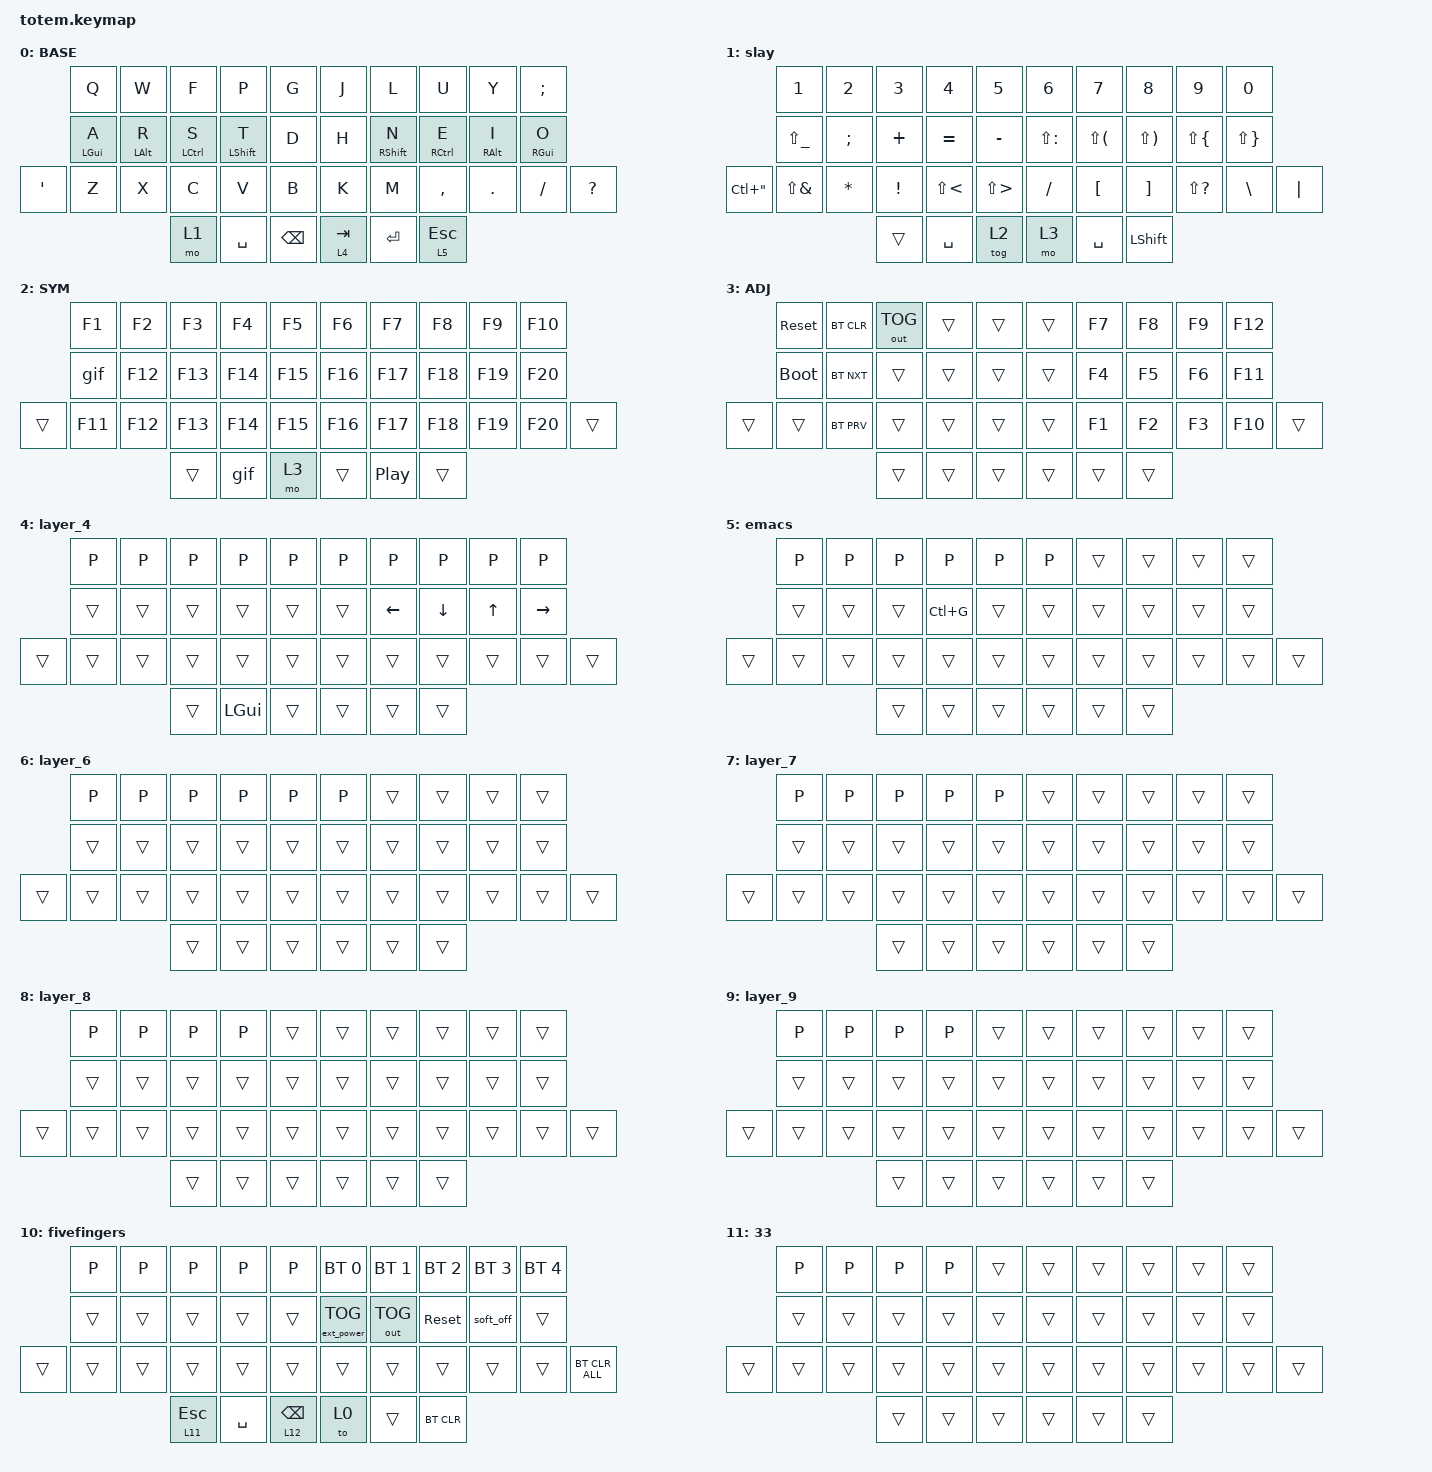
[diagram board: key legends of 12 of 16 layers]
//
//                                                        ▀▀▀▀▀     ▀▀▀▀▀          ▀▀█▀▀
//                                                        ▄▀▀▀▄  ▄  ▄▀▀▀▄  ▄  ▄▀▀▀▄  █  ▄▀▀▀▄
//                                                        █   █  █  █   █  █  █   █  █  █   █
//                                                         ▀▀▀   █   ▀▀▀   █   ▀▀▀   ▀   ▀▀▀
//                                                               █      ▄▄▄█▄▄▄    █   █  
//                                                               ▀      █  █  █     █▄█
//                                                             ▀▀▀▀▀    █  █  █      ▀
//                                                                      ▀  ▀  ▀
//
// ▄▄▄▄▄▄▄▄▄▄▄▄▄▄▄▄▄▄▄▄▄▄▄▄▄▄▄▄▄▄▄▄▄▄▄▄▄▄▄▄▄▄▄▄▄▄▄▄▄▄▄▄▄▄▄▄▄▄▄▄▄▄▄▄▄▄▄▄▄▄▄▄▄▄▄▄▄▄▄▄▄▄▄▄▄▄▄▄▄▄▄▄▄▄▄▄▄▄▄▄▄▄▄▄▄▄▄▄▄▄▄▄▄▄▄▄▄▄▄▄▄▄▄▄▄▄▄▄▄▄▄▄▄▄▄▄▄▄▄▄▄▄▄▄▄▄▄▄▄

#include <behaviors.dtsi>
#include <dt-bindings/zmk/bt.h>
#include <dt-bindings/zmk/ext_power.h>
#include <dt-bindings/zmk/keys.h>
#include <dt-bindings/zmk/outputs.h>

#define BASE 0
#define NAV  1
#define SYM  2
#define ADJ  3

&mt {
    quick-tap-ms = <100>;
    global-quick-tap;
    flavor = "tap-preferred";
    tapping-term-ms = <170>;
};

/ {
    combos {
        compatible = "zmk,combos";

        combo_esc {
            timeout-ms = <50>;
            key-positions = <0 1>;
            bindings = <&kp ESC>;
        };
    };

    macros {
        gif: gif {
            label = "giphy";
            compatible = "zmk,behavior-macro";
            #binding-cells = <0>;
            bindings =
                <&macro_press>,
                <&kp LSHFT>,
                <&macro_tap>,
                <&kp N2>,
                <&macro_release>,
                <&kp LSHFT>,
                <&macro_tap>,
                <&kp G &kp I &kp F>;
        };
    };

    keymap {
        compatible = "zmk,keymap";

        // ▄▄▄▄▄▄▄▄▄▄▄▄▄▄▄▄▄▄▄▄▄▄▄▄▄▄▄▄▄▄▄▄▄▄▄▄▄▄▄▄▄▄▄▄▄▄▄▄▄▄▄▄▄▄▄▄▄▄▄▄▄▄▄▄▄▄▄▄▄▄▄▄▄▄▄▄▄▄▄▄▄▄▄▄▄▄▄▄▄▄▄▄▄▄▄▄▄▄▄▄▄▄▄▄▄▄▄▄▄▄▄▄▄▄▄▄▄▄▄▄▄▄▄▄▄▄▄▄▄▄▄▄▄▄▄▄▄▄▄▄▄▄▄▄▄▄▄▄▄

        base_layer {
            // ┏━━━━━━━━━━━━━━━━━━━━━━━━━━━━━━━━━━━━━━━┓

            label = "BASE";

            // ┗━━━━━━━━━━━━━━━━━━━━━━━━━━━━━━━━━━━━━━━┛
            //             ┏━━━━━━━━━━━┳━━━━━━━━━━━┳━━━━━━━━━━━┳━━━━━━━━━━━┳━━━━━━━━━━━┓   ┏━━━━━━━━━━━┳━━━━━━━━━━━┳━━━━━━━━━━━┳━━━━━━━━━━━┳━━━━━━━━━━━┓
            //             ┃     Q     ┃     W     ┃     F     ┃     P     ┃     G     ┃   ┃     J     ┃     L     ┃     U     ┃     Y     ┃     ;     ┃
            //             ┣━━━━━━━━━━━╋━━━━━━━━━━━╋━━━━━━━━━━━╋━━━━━━━━━━━╋━━━━━━━━━━━┫   ┣━━━━━━━━━━━╋━━━━━━━━━━━╋━━━━━━━━━━━╋━━━━━━━━━━━╋━━━━━━━━━━━┫
            //             ┃     A     ┃     R     ┃     S     ┃     T     ┃     D     ┃   ┃     H     ┃     N     ┃     E     ┃     I     ┃     O     ┃
            // ┏━━━━━━━━━━━╋━━━━━━━━━━━╋━━━━━━━━━━━╋━━━━━━━━━━━╋━━━━━━━━━━━╋━━━━━━━━━━━┫   ┣━━━━━━━━━━━╋━━━━━━━━━━━╋━━━━━━━━━━━╋━━━━━━━━━━━╋━━━━━━━━━━━╋━━━━━━━━━━━┓
            // ┃           ┃     Z     ┃     X     ┃     C     ┃     V     ┃     B     ┃   ┃     K     ┃     M     ┃     ,     ┃     .     ┃     /     ┃           ┃
            // ┗━━━━━━━━━━━┻━━━━━━━━━━━┻━━━━━━━━━━━╋━━━━━━━━━━━╋━━━━━━━━━━━╋━━━━━━━━━━━┫   ┣━━━━━━━━━━━╋━━━━━━━━━━━╋━━━━━━━━━━━╋━━━━━━━━━━━┻━━━━━━━━━━━┻━━━━━━━━━━━┛
            //                                     ┃           ┃    TAB    ┃    SPC    ┃   ┃   ENTER   ┃   BSPC    ┃           ┃
            //                                     ┗━━━━━━━━━━━┻━━━━━━━━━━━┻━━━━━━━━━━━┛   ┗━━━━━━━━━━━┻━━━━━━━━━━━┻━━━━━━━━━━━┛

            bindings = <
                &kp Q       &kp W       &kp F        &kp P        &kp G            &kp J      &kp L        &kp U         &kp Y       &kp SEMI
                &mt LGUI A  &mt LALT R  &mt LCTRL S  &mt LSHFT T  &kp D            &kp H      &mt RSHFT N  &mt RCTRL E   &mt RALT I  &mt RGUI O
&kp APOSTROPHE  &kp Z       &kp X       &kp C        &kp V        &kp B            &kp K      &kp M        &kp COMMA     &kp DOT     &kp FSLH    &kp QUESTION
                                        &mo 1        &kp SPACE    &kp BACKSPACE    &lt 4 TAB  &kp RET      &lt 5 ESCAPE
            >;
        };

        // ▄▄▄▄▄▄▄▄▄▄▄▄▄▄▄▄▄▄▄▄▄▄▄▄▄▄▄▄▄▄▄▄▄▄▄▄▄▄▄▄▄▄▄▄▄▄▄▄▄▄▄▄▄▄▄▄▄▄▄▄▄▄▄▄▄▄▄▄▄▄▄▄▄▄▄▄▄▄▄▄▄▄▄▄▄▄▄▄▄▄▄▄▄▄▄▄▄▄▄▄▄▄▄▄▄▄▄▄▄▄▄▄▄▄▄▄▄▄▄▄▄▄▄▄▄▄▄▄▄▄▄▄▄▄▄▄▄▄▄▄▄▄▄▄▄▄▄▄▄

        slayer {
            // ┏━━━━━━━━━━━━━━━━━━━━━━━━━━━━━━━━━━━━━━━┓

            label = "slay";

            // ┗━━━━━━━━━━━━━━━━━━━━━━━━━━━━━━━━━━━━━━━┛
            //             ┏━━━━━━━━━━━┳━━━━━━━━━━━┳━━━━━━━━━━━┳━━━━━━━━━━━┳━━━━━━━━━━━┓   ┏━━━━━━━━━━━┳━━━━━━━━━━━┳━━━━━━━━━━━┳━━━━━━━━━━━┳━━━━━━━━━━━┓
            //             ┃           ┃           ┃     UP    ┃           ┃     {     ┃   ┃     }     ┃     7     ┃     8     ┃     9     ┃     +     ┃
            //             ┣━━━━━━━━━━━╋━━━━━━━━━━━╋━━━━━━━━━━━╋━━━━━━━━━━━╋━━━━━━━━━━━┫   ┣━━━━━━━━━━━╋━━━━━━━━━━━╋━━━━━━━━━━━╋━━━━━━━━━━━╋━━━━━━━━━━━┫
            //             ┃   SHIFT   ┃   LEFT    ┃    DOWN   ┃   RIGHT   ┃     [     ┃   ┃     ]     ┃     4     ┃     5     ┃     6     ┃     -     ┃
            // ┏━━━━━━━━━━━╋━━━━━━━━━━━╋━━━━━━━━━━━╋━━━━━━━━━━━╋━━━━━━━━━━━╋━━━━━━━━━━━┫   ┣━━━━━━━━━━━╋━━━━━━━━━━━╋━━━━━━━━━━━╋━━━━━━━━━━━╋━━━━━━━━━━━╋━━━━━━━━━━━┓
            // ┃           ┃           ┃   P UP    ┃  C LOCK   ┃  P DOWN   ┃     (     ┃   ┃     )     ┃     1     ┃     2     ┃     3     ┃     *     ┃           ┃
            // ┗━━━━━━━━━━━┻━━━━━━━━━━━┻━━━━━━━━━━━╋━━━━━━━━━━━╋━━━━━━━━━━━╋━━━━━━━━━━━┫   ┣━━━━━━━━━━━╋━━━━━━━━━━━╋━━━━━━━━━━━╋━━━━━━━━━━━┻━━━━━━━━━━━┻━━━━━━━━━━━┛
            //                                     ┃           ┃    TAB    ┃    SPC    ┃   ┃    DEL    ┃     0     ┃           ┃
            //                                     ┗━━━━━━━━━━━┻━━━━━━━━━━━┻━━━━━━━━━━━┛   ┗━━━━━━━━━━━┻━━━━━━━━━━━┻━━━━━━━━━━━┛

            bindings = <
                       &kp N1         &kp N2    &kp N3    &kp N4      &kp N5        &kp N6         &kp N7        &kp N8          &kp N9            &kp N0
                       &kp LS(UNDER)  &kp SEMI  &kp PLUS  &kp EQUAL   &kp MINUS     &kp LS(COLON)  &kp LS(LPAR)  &kp LS(RPAR)    &kp LS(LBRC)      &kp LS(RBRC)
&kp LC(DOUBLE_QUOTES)  &kp LS(AMPS)   &kp STAR  &kp EXCL  &kp LS(LT)  &kp LS(GT)    &kp FSLH       &kp LBKT      &kp RBKT        &kp LS(QUESTION)  &kp BSLH      &kp PIPE
                                                &trans    &kp SPACE   &tog 2        &mo 3          &kp SPACE     &kp LEFT_SHIFT
            >;
        };

        // ▄▄▄▄▄▄▄▄▄▄▄▄▄▄▄▄▄▄▄▄▄▄▄▄▄▄▄▄▄▄▄▄▄▄▄▄▄▄▄▄▄▄▄▄▄▄▄▄▄▄▄▄▄▄▄▄▄▄▄▄▄▄▄▄▄▄▄▄▄▄▄▄▄▄▄▄▄▄▄▄▄▄▄▄▄▄▄▄▄▄▄▄▄▄▄▄▄▄▄▄▄▄▄▄▄▄▄▄▄▄▄▄▄▄▄▄▄▄▄▄▄▄▄▄▄▄▄▄▄▄▄▄▄▄▄▄▄▄▄▄▄▄▄▄▄▄▄▄▄

        func {
            // ┏━━━━━━━━━━━━━━━━━━━━━━━━━━━━━━━━━━━━━━━┓

            label = "SYM";

            // ┗━━━━━━━━━━━━━━━━━━━━━━━━━━━━━━━━━━━━━━━┛
            //             ┏━━━━━━━━━━━┳━━━━━━━━━━━┳━━━━━━━━━━━┳━━━━━━━━━━━┳━━━━━━━━━━━┓   ┏━━━━━━━━━━━┳━━━━━━━━━━━┳━━━━━━━━━━━┳━━━━━━━━━━━┳━━━━━━━━━━━┓
            //             ┃     !     ┃     @     ┃     #     ┃     $     ┃     %     ┃   ┃     ˆ     ┃     &     ┃     Ü     ┃     '     ┃     "     ┃
            //             ┣━━━━━━━━━━━╋━━━━━━━━━━━╋━━━━━━━━━━━╋━━━━━━━━━━━╋━━━━━━━━━━━┫   ┣━━━━━━━━━━━╋━━━━━━━━━━━╋━━━━━━━━━━━╋━━━━━━━━━━━╋━━━━━━━━━━━┫
            //             ┃     Ä     ┃           ┃    SZ     ┃           ┃           ┃   ┃   MUTE    ┃   YEN     ┃   EURO    ┃  POUND    ┃     Ö     ┃
            // ┏━━━━━━━━━━━╋━━━━━━━━━━━╋━━━━━━━━━━━╋━━━━━━━━━━━╋━━━━━━━━━━━╋━━━━━━━━━━━┫   ┣━━━━━━━━━━━╋━━━━━━━━━━━╋━━━━━━━━━━━╋━━━━━━━━━━━╋━━━━━━━━━━━╋━━━━━━━━━━━┓
            // ┃           ┃  EMAIL1   ┃  EMAIL2   ┃           ┃           ┃           ┃   ┃   VOL-    ┃   VOL+    ┃   LAST    ┃   NEXT    ┃     \     ┃           ┃
            // ┗━━━━━━━━━━━┻━━━━━━━━━━━┻━━━━━━━━━━━╋━━━━━━━━━━━╋━━━━━━━━━━━╋━━━━━━━━━━━┫   ┣━━━━━━━━━━━╋━━━━━━━━━━━╋━━━━━━━━━━━╋━━━━━━━━━━━┻━━━━━━━━━━━┻━━━━━━━━━━━┛
            //                                     ┃           ┃    GIF    ┃    ADJ    ┃   ┃           ┃           ┃           ┃
            //                                     ┗━━━━━━━━━━━┻━━━━━━━━━━━┻━━━━━━━━━━━┛   ┗━━━━━━━━━━━┻━━━━━━━━━━━┻━━━━━━━━━━━┛

            bindings = <
        &kp F1   &kp F2   &kp F3   &kp F4   &kp F5     &kp F6   &kp F7    &kp F8   &kp F9   &kp F10
        &gif     &kp F12  &kp F13  &kp F14  &kp F15    &kp F16  &kp F17   &kp F18  &kp F19  &kp F20
&trans  &kp F11  &kp F12  &kp F13  &kp F14  &kp F15    &kp F16  &kp F17   &kp F18  &kp F19  &kp F20  &trans
                          &trans   &gif     &mo 3      &trans   &kp C_PP  &trans
            >;
        };

        // ▄▄▄▄▄▄▄▄▄▄▄▄▄▄▄▄▄▄▄▄▄▄▄▄▄▄▄▄▄▄▄▄▄▄▄▄▄▄▄▄▄▄▄▄▄▄▄▄▄▄▄▄▄▄▄▄▄▄▄▄▄▄▄▄▄▄▄▄▄▄▄▄▄▄▄▄▄▄▄▄▄▄▄▄▄▄▄▄▄▄▄▄▄▄▄▄▄▄▄▄▄▄▄▄▄▄▄▄▄▄▄▄▄▄▄▄▄▄▄▄▄▄▄▄▄▄▄▄▄▄▄▄▄▄▄▄▄▄▄▄▄▄▄▄▄▄▄▄▄

        adjust_layer {
            // ┏━━━━━━━━━━━━━━━━━━━━━━━━━━━━━━━━━━━━━━━┓

            label = "ADJ";

            // ┗━━━━━━━━━━━━━━━━━━━━━━━━━━━━━━━━━━━━━━━┛
            //             ┏━━━━━━━━━━━┳━━━━━━━━━━━┳━━━━━━━━━━━┳━━━━━━━━━━━┳━━━━━━━━━━━┓   ┏━━━━━━━━━━━┳━━━━━━━━━━━┳━━━━━━━━━━━┳━━━━━━━━━━━┳━━━━━━━━━━━┓
            //             ┃   RESET   ┃ BT CLEAR  ┃  OUT TOG  ┃           ┃           ┃   ┃           ┃    F7     ┃    F8     ┃    F9     ┃    F12    ┃
            //             ┣━━━━━━━━━━━╋━━━━━━━━━━━╋━━━━━━━━━━━╋━━━━━━━━━━━╋━━━━━━━━━━━┫   ┣━━━━━━━━━━━╋━━━━━━━━━━━╋━━━━━━━━━━━╋━━━━━━━━━━━╋━━━━━━━━━━━┫
            //             ┃ BOOTLOAD  ┃ BT NEXT   ┃           ┃           ┃           ┃   ┃           ┃    F4     ┃    F5     ┃    F6     ┃    F11    ┃
            // ┏━━━━━━━━━━━╋━━━━━━━━━━━╋━━━━━━━━━━━╋━━━━━━━━━━━╋━━━━━━━━━━━╋━━━━━━━━━━━┫   ┣━━━━━━━━━━━╋━━━━━━━━━━━╋━━━━━━━━━━━╋━━━━━━━━━━━╋━━━━━━━━━━━╋━━━━━━━━━━━┓
            // ┃           ┃           ┃ BT PREV   ┃           ┃           ┃           ┃   ┃           ┃    F1     ┃    F2     ┃    F3     ┃    F10    ┃           ┃
            // ┗━━━━━━━━━━━┻━━━━━━━━━━━┻━━━━━━━━━━━╋━━━━━━━━━━━╋━━━━━━━━━━━╋━━━━━━━━━━━┫   ┣━━━━━━━━━━━╋━━━━━━━━━━━╋━━━━━━━━━━━╋━━━━━━━━━━━┻━━━━━━━━━━━┻━━━━━━━━━━━┛
            //                                     ┃           ┃           ┃           ┃   ┃           ┃           ┃           ┃
            //                                     ┗━━━━━━━━━━━┻━━━━━━━━━━━┻━━━━━━━━━━━┛   ┗━━━━━━━━━━━┻━━━━━━━━━━━┻━━━━━━━━━━━┛

            bindings = <
        &sys_reset   &bt BT_CLR  &out OUT_TOG  &trans  &trans    &trans  &kp F7  &kp F8  &kp F9  &kp F12
        &bootloader  &bt BT_NXT  &trans        &trans  &trans    &trans  &kp F4  &kp F5  &kp F6  &kp F11
&trans  &trans       &bt BT_PRV  &trans        &trans  &trans    &trans  &kp F1  &kp F2  &kp F3  &kp F10  &trans
                                 &trans        &trans  &trans    &trans  &trans  &trans
            >;
        };

        layer_4 {
            bindings = <
        &kp P   &kp P   &kp P   &kp P         &kp P     &kp P   &kp P     &kp P     &kp P         &kp P
        &trans  &trans  &trans  &trans        &trans    &trans  &kp LEFT  &kp DOWN  &kp UP_ARROW  &kp RIGHT
&trans  &trans  &trans  &trans  &trans        &trans    &trans  &trans    &trans    &trans        &trans     &trans
                        &trans  &kp LEFT_GUI  &trans    &trans  &trans    &trans
            >;
        };

        emacs {
            bindings = <
        &kp P   &kp P   &kp P   &kp P      &kp P     &kp P   &trans  &trans  &trans  &trans
        &trans  &trans  &trans  &kp LC(G)  &trans    &trans  &trans  &trans  &trans  &trans
&trans  &trans  &trans  &trans  &trans     &trans    &trans  &trans  &trans  &trans  &trans  &trans
                        &trans  &trans     &trans    &trans  &trans  &trans
            >;
        };

        layer_6 {
            bindings = <
        &kp P   &kp P   &kp P   &kp P   &kp P     &kp P   &trans  &trans  &trans  &trans
        &trans  &trans  &trans  &trans  &trans    &trans  &trans  &trans  &trans  &trans
&trans  &trans  &trans  &trans  &trans  &trans    &trans  &trans  &trans  &trans  &trans  &trans
                        &trans  &trans  &trans    &trans  &trans  &trans
            >;
        };

        layer_7 {
            bindings = <
        &kp P   &kp P   &kp P   &kp P   &kp P     &trans  &trans  &trans  &trans  &trans
        &trans  &trans  &trans  &trans  &trans    &trans  &trans  &trans  &trans  &trans
&trans  &trans  &trans  &trans  &trans  &trans    &trans  &trans  &trans  &trans  &trans  &trans
                        &trans  &trans  &trans    &trans  &trans  &trans
            >;
        };

        layer_8 {
            bindings = <
        &kp P   &kp P   &kp P   &kp P   &trans    &trans  &trans  &trans  &trans  &trans
        &trans  &trans  &trans  &trans  &trans    &trans  &trans  &trans  &trans  &trans
&trans  &trans  &trans  &trans  &trans  &trans    &trans  &trans  &trans  &trans  &trans  &trans
                        &trans  &trans  &trans    &trans  &trans  &trans
            >;
        };

        layer_9 {
            bindings = <
        &kp P   &kp P   &kp P   &kp P   &trans    &trans  &trans  &trans  &trans  &trans
        &trans  &trans  &trans  &trans  &trans    &trans  &trans  &trans  &trans  &trans
&trans  &trans  &trans  &trans  &trans  &trans    &trans  &trans  &trans  &trans  &trans  &trans
                        &trans  &trans  &trans    &trans  &trans  &trans
            >;
        };

        fivefingers {
            bindings = <
        &kp P   &kp P   &kp P          &kp P      &kp P               &bt BT_SEL 0       &bt BT_SEL 1  &bt BT_SEL 2  &bt BT_SEL 3  &bt BT_SEL 4
        &trans  &trans  &trans         &trans     &trans              &ext_power EP_TOG  &out OUT_TOG  &sys_reset    &soft_off     &trans
&trans  &trans  &trans  &trans         &trans     &trans              &trans             &trans        &trans        &trans        &trans        &bt BT_CLR_ALL
                        &lt 11 ESCAPE  &kp SPACE  &lt 12 BACKSPACE    &to 0              &trans        &bt BT_CLR
            >;
        };

        ff1 {
            bindings = <
        &kp P   &kp P   &kp P   &kp P   &trans    &trans  &trans  &trans  &trans  &trans
        &trans  &trans  &trans  &trans  &trans    &trans  &trans  &trans  &trans  &trans
&trans  &trans  &trans  &trans  &trans  &trans    &trans  &trans  &trans  &trans  &trans  &trans
                        &trans  &trans  &trans    &trans  &trans  &trans
            >;

            label = "33";
        };

        ff2 {
            bindings = <
        &kp P   &kp P   &kp P   &kp P   &trans    &trans  &trans  &trans  &trans  &trans
        &trans  &trans  &trans  &trans  &trans    &trans  &trans  &trans  &trans  &trans
&trans  &trans  &trans  &trans  &trans  &trans    &trans  &trans  &trans  &trans  &trans  &trans
                        &trans  &trans  &trans    &trans  &trans  &trans
            >;

            label = "fff";
        };

        ff3 {
            bindings = <
        &kp P   &kp P   &kp P   &kp P   &trans    &trans  &trans  &trans  &trans  &trans
        &trans  &trans  &trans  &trans  &trans    &trans  &trans  &trans  &trans  &trans
&trans  &trans  &trans  &trans  &trans  &trans    &trans  &trans  &trans  &trans  &trans  &trans
                        &trans  &trans  &trans    &trans  &trans  &trans
            >;
        };

        layer_14 {
            bindings = <
        &kp P   &kp P   &kp P   &kp P   &trans    &trans  &trans  &trans  &trans  &trans
        &trans  &trans  &trans  &trans  &trans    &trans  &trans  &trans  &trans  &trans
&trans  &trans  &trans  &trans  &trans  &trans    &trans  &trans  &trans  &trans  &trans  &trans
                        &trans  &trans  &trans    &trans  &trans  &trans
            >;
        };

        layer_15 {
            bindings = <
        &kp P   &kp P   &kp P   &kp P   &kp P     &trans  &trans  &trans  &trans  &trans
        &trans  &trans  &trans  &trans  &trans    &trans  &trans  &trans  &trans  &trans
&trans  &trans  &trans  &trans  &trans  &trans    &trans  &trans  &trans  &trans  &trans  &trans
                        &trans  &trans  &trans    &trans  &trans  &trans
            >;
        };
    };
};
